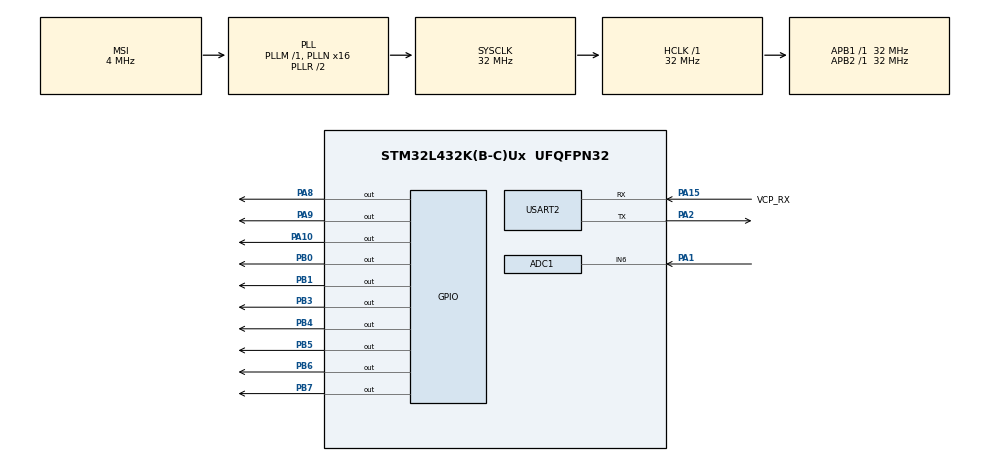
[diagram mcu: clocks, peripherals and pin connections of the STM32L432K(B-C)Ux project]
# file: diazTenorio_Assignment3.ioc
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ADC1.Channel-0\#ChannelRegularConversion=ADC_CHANNEL_6
ADC1.NbrOfConversionFlag=1
ADC1.OffsetNumber-0\#ChannelRegularConversion=ADC_OFFSET_NONE
ADC1.Rank-0\#ChannelRegularConversion=1
ADC1.SamplingTime-0\#ChannelRegularConversion=ADC_SAMPLETIME_2CYCLES_5
ADC1.master=1
Mcu.Family=STM32L4
Mcu.Name=STM32L432K(B-C)Ux
Mcu.Package=UFQFPN32
NVIC.PriorityGroup=NVIC_PRIORITYGROUP_4
PA0.GPIO_Label=MCO [High speed clock in]
PA0.Mode=HSE-External-Clock-Source-for-LittleOrca
PA0.Signal=RCC_CK_IN
PA1.Signal=ADCx_IN6
PA10.Signal=GPIO_Output
PA13\ (JTMS-SWDIO).GPIO_Label=SWDIO
PA13\ (JTMS-SWDIO).Mode=Serial_Wire
PA13\ (JTMS-SWDIO).Signal=SYS_JTMS-SWDIO
PA14\ (JTCK-SWCLK).GPIO_Label=SWCLK
PA14\ (JTCK-SWCLK).Mode=Serial_Wire
PA14\ (JTCK-SWCLK).Signal=SYS_JTCK-SWCLK
PA15\ (JTDI).GPIO_Label=VCP_RX
PA15\ (JTDI).Mode=Asynchronous
PA15\ (JTDI).Signal=USART2_RX
PA2.Mode=Asynchronous
PA2.Signal=USART2_TX
PA8.Signal=GPIO_Output
PA9.Signal=GPIO_Output
PB0.Signal=GPIO_Output
PB1.Signal=GPIO_Output
PB3\ (JTDO-TRACESWO).Signal=GPIO_Output
PB4\ (NJTRST).Signal=GPIO_Output
PB5.Signal=GPIO_Output
PB6.Signal=GPIO_Output
PB7.Signal=GPIO_Output
PC14-OSC32_IN\ (PC14).Mode=LSE-External-Oscillator
PC14-OSC32_IN\ (PC14).Signal=RCC_OSC32_IN
PC15-OSC32_OUT\ (PC15).Mode=LSE-External-Oscillator
PC15-OSC32_OUT\ (PC15).Signal=RCC_OSC32_OUT
ProjectManager.HeapSize=0x200
ProjectManager.StackSize=0x400
ProjectManager.TargetToolchain=STM32CubeIDE
RCC.ADCFreq_Value=32000000
RCC.AHBFreq_Value=32000000
RCC.APB1Freq_Value=32000000
RCC.APB1TimFreq_Value=32000000
RCC.APB2Freq_Value=32000000
RCC.APB2TimFreq_Value=32000000
RCC.CortexFreq_Value=32000000
RCC.HCLKFreq_Value=32000000
RCC.HSE_VALUE=8000000
RCC.HSI16_VALUE=16000000
RCC.HSI48_VALUE=48000000
RCC.HSI_VALUE=16000000
RCC.MSI_VALUE=4000000
RCC.PLLMUL=RCC_PLLMUL_4
RCC.PLLN=16
RCC.PLLSAI1N=16
RCC.SYSCLKFreq_VALUE=32000000
RCC.SYSCLKSource=RCC_SYSCLKSOURCE_PLLCLK
RCC.USBFreq_Value=32000000
RCC.VCOOutputFreq_Value=64000000
SH.ADCx_IN6.0=ADC1_IN6,IN6-Single-Ended
USART2.VirtualMode-Asynchronous=VM_ASYNC
board=NUCLEO-L432KC

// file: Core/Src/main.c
/* USER CODE BEGIN Header */
/*******************************************************************************
  * File Name          : main.c
  * Description        : Reads the voltage from a thermistor MCP9700AE to sense
  * 					 the temperature. The values is read through the ADC and
  * 					 the digital value of the voltage is converted to analog and
  * 					 finally to temperature in Celsius. The temperature is printed
  * 					 through vcn and a LCD display, with a light code depending on the
  * 					 temperature range.
  *
  * Author:              Daniela Diaz Tenorio
  * Date:                March 19st 2020
  ******************************************************************************
  */
/* USER CODE END Header */

#include "main.h"

/* USER CODE BEGIN Includes */
#include "stdio.h"
/* USER CODE END Includes */

ADC_HandleTypeDef hadc1;

UART_HandleTypeDef huart2;

void SystemClock_Config(void);
static void MX_GPIO_Init(void);
static void MX_USART2_UART_Init(void);
static void MX_ADC1_Init(void);

/*
  * FUNCTION           : readSensor
  * DESCRIPTION        : Reads and return the voltage provided by the thermistor using
  * 					 a 12 bits ADC.
  * 					 Used pin PA1
  * PARAMETERS		   : ADC_HandleTypeDef *hadc1: the adc configured to be used.
  *
  * RETURN			   : int digitalVoltage: digital voltage read
  */
uint16_t readSensor(ADC_HandleTypeDef *hadc1)
{
	uint16_t digitalVoltage = 0;

	HAL_ADC_Start(&*hadc1);
	HAL_ADC_PollForConversion(&*hadc1, 1000);
	digitalVoltage = HAL_ADC_GetValue(&*hadc1);
	HAL_Delay(2000);
	HAL_ADC_Stop(&*hadc1);

	return digitalVoltage;
}

/*
  * FUNCTION           : getAnalogVoltage
  * DESCRIPTION        : Converts a digital 12 bits digital voltage to analog voltage
  * 					 using an specific resolution.
  *
  * PARAMETERS		   : const float adcResolution: the resolution for the ADC
  * 					adcResolution = (VrefMax - VrefMin)/(2pow(12))
  * 					adcResolution = (3600mv - 0 mv)/(2pow(12))
  * 					adcResolution = 0.87890625
  *
  * RETURN			   : float analogVoltage: equivalent analogVoltage
  */
float getAnalogVoltage(const float adcResolution)
{
	uint16_t digitalVoltage = 0;
	float analogVoltage = 0;

	digitalVoltage = readSensor(&hadc1);
	analogVoltage = adcResolution * digitalVoltage;

	return analogVoltage;
}

/*
  * FUNCTION           : getTemperature
  * DESCRIPTION        : Obtained the temperature in Celsius from an analog voltage value in mV.
  * 					 To perform the conversion it was required to obtained the formula
  * 					 that simulates the MCP7900AE behavior.
  * 					 temperature = (analogVoltage / 10) - 50;
  *
  * PARAMETERS		   : const float adcResolution: the adc resolution.
  * 					 const int8_t callibration: callibration value for the thermistor
  * 					 after testing the sensor several times the best value is -8
  *
  * RETURN			   : float temperature: the equivalent temperature in Celsius.
  */
float getTemperature(const float adcResolution, const int8_t callibration)
{
	float analogVoltage = 0;
	float temperature = 0;

	analogVoltage = getAnalogVoltage(adcResolution);
	temperature = (analogVoltage / 10) - 50 - callibration;

	return temperature;
}

/*
  * FUNCTION           : printLcdVcn
  * DESCRIPTION        : Print the temperature value in the LCD display and through a vcn
  * 					 (serial port).
  * 					 For this I used HD44780 file
  * 					 Used PA2 for the vcn
  *
  * PARAMETERS		   : float temperature: the temperature.
  *
  * RETURN			   : no return.
  */
void printLcdVcn(float temperature)
{
	char printBuffer [16] = { 0 };

	//print on vcn
	printf("Temperature is %.2f Celsius \n", temperature);

	// print on display
	HD44780_GotoXY(0, 0);
	HD44780_PutStr("Temperature is ");
	sprintf(printBuffer, " %.2f Celsius", temperature);
	HD44780_GotoXY(0, 1);
	HD44780_PutStr(printBuffer);
}

/*
  * FUNCTION           : rgbLed
  * DESCRIPTION        : It flashes a RGB LED depending of the range of terperature that the
  * 					 thermistor is, the color code is:
  * 					 Blue : temperature <= 20.5
  * 					 Green : 20.5 < temperature <= 37.3
  * 					 Orange/yellow : 37.3 < temperature <= 39.5
  * 					 Red : temperature > 39.5
  *
  * 					 The pins used are:
  * 					 PA8 : Red
  * 					 PA9 : Green
  * 					 PA10 : Blue
  *
  * PARAMETERS		   : float temperature: the temperature.
  *
  * RETURN			   : no return.
  */
void rgbLed(float temperature)
{
	if (temperature <= 20.5)
	{ // flash Blue
		HAL_GPIO_WritePin(GPIOA, GPIO_PIN_10, GPIO_PIN_SET);
		HAL_GPIO_WritePin(GPIOA, GPIO_PIN_9, GPIO_PIN_RESET);
		HAL_GPIO_WritePin(GPIOA, GPIO_PIN_8, GPIO_PIN_RESET);
		HAL_Delay(1000);
	}
	else if (temperature > 20.5 && temperature <= 37.3)
	{ // flash Green
		HAL_GPIO_WritePin(GPIOA, GPIO_PIN_9, GPIO_PIN_SET);
		HAL_GPIO_WritePin(GPIOA, GPIO_PIN_8, GPIO_PIN_RESET);
		HAL_GPIO_WritePin(GPIOA, GPIO_PIN_10, GPIO_PIN_RESET);
		HAL_Delay(1000);
	}
	else if (temperature > 37.3 && temperature <= 39.5)
	{ // flash Orange/yellow
		HAL_GPIO_WritePin(GPIOA, GPIO_PIN_9, GPIO_PIN_SET);
		HAL_GPIO_WritePin(GPIOA, GPIO_PIN_8, GPIO_PIN_SET);
		HAL_GPIO_WritePin(GPIOA, GPIO_PIN_10, GPIO_PIN_RESET);
		HAL_Delay(1000);
	}
	else
	{
		HAL_GPIO_WritePin(GPIOA, GPIO_PIN_8, GPIO_PIN_SET); // flash Red
		HAL_GPIO_WritePin(GPIOA, GPIO_PIN_9, GPIO_PIN_RESET);
		HAL_GPIO_WritePin(GPIOA, GPIO_PIN_10, GPIO_PIN_RESET);
		HAL_Delay(1000);
	}
}

int main(void)
{

  /* MCU Configuration--------------------------------------------------------*/

  /* Reset of all peripherals, Initializes the Flash interface and the Systick. */
  HAL_Init();

  /* USER CODE BEGIN Init */
  HD44780_Init();
  /* USER CODE END Init */

  /* Configure the system clock */
  SystemClock_Config();

  /* Initialize all configured peripherals */
  MX_GPIO_Init();
  MX_USART2_UART_Init();
  MX_ADC1_Init();
  /* USER CODE BEGIN 2 */
  const float adcResolution = 0.87890625; // (VrefMax - VrefMin)/(2pow(12))
  const int8_t callibration = -8; // temperature sensor callibration value
  float temperature = 0;
  /* USER CODE END 2 */

  /* Infinite loop */
  /* USER CODE BEGIN WHILE */
  while (1)
  {

	 temperature = getTemperature(adcResolution,callibration); //get temperature from the thermistor
	 printLcdVcn(temperature); // print temperature values
	 rgbLed(temperature); // flash the Led following the color code temperatures ranges

    /* USER CODE END WHILE */

  }
}

void SystemClock_Config(void)
{
  RCC_OscInitTypeDef RCC_OscInitStruct = {0};
  RCC_ClkInitTypeDef RCC_ClkInitStruct = {0};
  RCC_PeriphCLKInitTypeDef PeriphClkInit = {0};

  /** Configure LSE Drive Capability
  */
  HAL_PWR_EnableBkUpAccess();
  __HAL_RCC_LSEDRIVE_CONFIG(RCC_LSEDRIVE_LOW);
  /** Initializes the CPU, AHB and APB busses clocks
  */
  RCC_OscInitStruct.OscillatorType = RCC_OSCILLATORTYPE_LSE|RCC_OSCILLATORTYPE_MSI;
  RCC_OscInitStruct.LSEState = RCC_LSE_ON;
  RCC_OscInitStruct.MSIState = RCC_MSI_ON;
  RCC_OscInitStruct.MSICalibrationValue = 0;
  RCC_OscInitStruct.MSIClockRange = RCC_MSIRANGE_6;
  RCC_OscInitStruct.PLL.PLLState = RCC_PLL_ON;
  RCC_OscInitStruct.PLL.PLLSource = RCC_PLLSOURCE_MSI;
  RCC_OscInitStruct.PLL.PLLM = 1;
  RCC_OscInitStruct.PLL.PLLN = 16;
  RCC_OscInitStruct.PLL.PLLP = RCC_PLLP_DIV7;
  RCC_OscInitStruct.PLL.PLLQ = RCC_PLLQ_DIV2;
  RCC_OscInitStruct.PLL.PLLR = RCC_PLLR_DIV2;
  if (HAL_RCC_OscConfig(&RCC_OscInitStruct) != HAL_OK)
  {
    Error_Handler();
  }
  /** Initializes the CPU, AHB and APB busses clocks
  */
  RCC_ClkInitStruct.ClockType = RCC_CLOCKTYPE_HCLK|RCC_CLOCKTYPE_SYSCLK
                              |RCC_CLOCKTYPE_PCLK1|RCC_CLOCKTYPE_PCLK2;
  RCC_ClkInitStruct.SYSCLKSource = RCC_SYSCLKSOURCE_PLLCLK;
  RCC_ClkInitStruct.AHBCLKDivider = RCC_SYSCLK_DIV1;
  RCC_ClkInitStruct.APB1CLKDivider = RCC_HCLK_DIV1;
  RCC_ClkInitStruct.APB2CLKDivider = RCC_HCLK_DIV1;

  if (HAL_RCC_ClockConfig(&RCC_ClkInitStruct, FLASH_LATENCY_1) != HAL_OK)
  {
    Error_Handler();
  }
  PeriphClkInit.PeriphClockSelection = RCC_PERIPHCLK_USART2|RCC_PERIPHCLK_ADC;
  PeriphClkInit.Usart2ClockSelection = RCC_USART2CLKSOURCE_PCLK1;
  PeriphClkInit.AdcClockSelection = RCC_ADCCLKSOURCE_PLLSAI1;
  PeriphClkInit.PLLSAI1.PLLSAI1Source = RCC_PLLSOURCE_MSI;
  PeriphClkInit.PLLSAI1.PLLSAI1M = 1;
  PeriphClkInit.PLLSAI1.PLLSAI1N = 16;
  PeriphClkInit.PLLSAI1.PLLSAI1P = RCC_PLLP_DIV7;
  PeriphClkInit.PLLSAI1.PLLSAI1Q = RCC_PLLQ_DIV2;
  PeriphClkInit.PLLSAI1.PLLSAI1R = RCC_PLLR_DIV2;
  PeriphClkInit.PLLSAI1.PLLSAI1ClockOut = RCC_PLLSAI1_ADC1CLK;
  if (HAL_RCCEx_PeriphCLKConfig(&PeriphClkInit) != HAL_OK)
  {
    Error_Handler();
  }
  /** Configure the main internal regulator output voltage
  */
  if (HAL_PWREx_ControlVoltageScaling(PWR_REGULATOR_VOLTAGE_SCALE1) != HAL_OK)
  {
    Error_Handler();
  }
  /** Enable MSI Auto calibration
  */
  HAL_RCCEx_EnableMSIPLLMode();
}

static void MX_ADC1_Init(void)
{

  ADC_ChannelConfTypeDef sConfig = {0};

  /** Common config
  */
  hadc1.Instance = ADC1;
  hadc1.Init.ClockPrescaler = ADC_CLOCK_ASYNC_DIV1;
  hadc1.Init.Resolution = ADC_RESOLUTION_12B;
  hadc1.Init.DataAlign = ADC_DATAALIGN_RIGHT;
  hadc1.Init.ScanConvMode = ADC_SCAN_DISABLE;
  hadc1.Init.EOCSelection = ADC_EOC_SINGLE_CONV;
  hadc1.Init.LowPowerAutoWait = DISABLE;
  hadc1.Init.ContinuousConvMode = DISABLE;
  hadc1.Init.NbrOfConversion = 1;
  hadc1.Init.DiscontinuousConvMode = DISABLE;
  hadc1.Init.NbrOfDiscConversion = 1;
  hadc1.Init.ExternalTrigConv = ADC_SOFTWARE_START;
  hadc1.Init.ExternalTrigConvEdge = ADC_EXTERNALTRIGCONVEDGE_NONE;
  hadc1.Init.DMAContinuousRequests = DISABLE;
  hadc1.Init.Overrun = ADC_OVR_DATA_PRESERVED;
  hadc1.Init.OversamplingMode = DISABLE;
  if (HAL_ADC_Init(&hadc1) != HAL_OK)
  {
    Error_Handler();
  }
  /** Configure Regular Channel
  */
  sConfig.Channel = ADC_CHANNEL_6;
  sConfig.Rank = ADC_REGULAR_RANK_1;
  sConfig.SamplingTime = ADC_SAMPLETIME_2CYCLES_5;
  sConfig.SingleDiff = ADC_SINGLE_ENDED;
  sConfig.OffsetNumber = ADC_OFFSET_NONE;
  sConfig.Offset = 0;
  if (HAL_ADC_ConfigChannel(&hadc1, &sConfig) != HAL_OK)
  {
    Error_Handler();
  }

}

static void MX_USART2_UART_Init(void)
{

  huart2.Instance = USART2;
  huart2.Init.BaudRate = 115200;
  huart2.Init.WordLength = UART_WORDLENGTH_8B;
  huart2.Init.StopBits = UART_STOPBITS_1;
  huart2.Init.Parity = UART_PARITY_NONE;
  huart2.Init.Mode = UART_MODE_TX_RX;
  huart2.Init.HwFlowCtl = UART_HWCONTROL_NONE;
  huart2.Init.OverSampling = UART_OVERSAMPLING_16;
  huart2.Init.OneBitSampling = UART_ONE_BIT_SAMPLE_DISABLE;
  huart2.AdvancedInit.AdvFeatureInit = UART_ADVFEATURE_NO_INIT;
  if (HAL_UART_Init(&huart2) != HAL_OK)
  {
    Error_Handler();
  }

}

static void MX_GPIO_Init(void)
{
  GPIO_InitTypeDef GPIO_InitStruct = {0};

  /* GPIO Ports Clock Enable */
  __HAL_RCC_GPIOC_CLK_ENABLE();
  __HAL_RCC_GPIOA_CLK_ENABLE();
  __HAL_RCC_GPIOB_CLK_ENABLE();

  /*Configure GPIO pin Output Level */
  HAL_GPIO_WritePin(GPIOB, GPIO_PIN_0|GPIO_PIN_1|GPIO_PIN_3|GPIO_PIN_4
                          |GPIO_PIN_5|GPIO_PIN_6|GPIO_PIN_7, GPIO_PIN_RESET);

  /*Configure GPIO pin Output Level */
  HAL_GPIO_WritePin(GPIOA, GPIO_PIN_8|GPIO_PIN_9|GPIO_PIN_10, GPIO_PIN_RESET);

  /*Configure GPIO pins : PB0 PB1 PB3 PB4
                           PB5 PB6 PB7 */
  GPIO_InitStruct.Pin = GPIO_PIN_0|GPIO_PIN_1|GPIO_PIN_3|GPIO_PIN_4
                          |GPIO_PIN_5|GPIO_PIN_6|GPIO_PIN_7;
  GPIO_InitStruct.Mode = GPIO_MODE_OUTPUT_PP;
  GPIO_InitStruct.Pull = GPIO_NOPULL;
  GPIO_InitStruct.Speed = GPIO_SPEED_FREQ_LOW;
  HAL_GPIO_Init(GPIOB, &GPIO_InitStruct);

  /*Configure GPIO pins : PA8 PA9 PA10 */
  GPIO_InitStruct.Pin = GPIO_PIN_8|GPIO_PIN_9|GPIO_PIN_10;
  GPIO_InitStruct.Mode = GPIO_MODE_OUTPUT_PP;
  GPIO_InitStruct.Pull = GPIO_NOPULL;
  GPIO_InitStruct.Speed = GPIO_SPEED_FREQ_LOW;
  HAL_GPIO_Init(GPIOA, &GPIO_InitStruct);

}

void Error_Handler(void)
{
}

/************************ (C) COPYRIGHT STMicroelectronics *****END OF FILE****/
